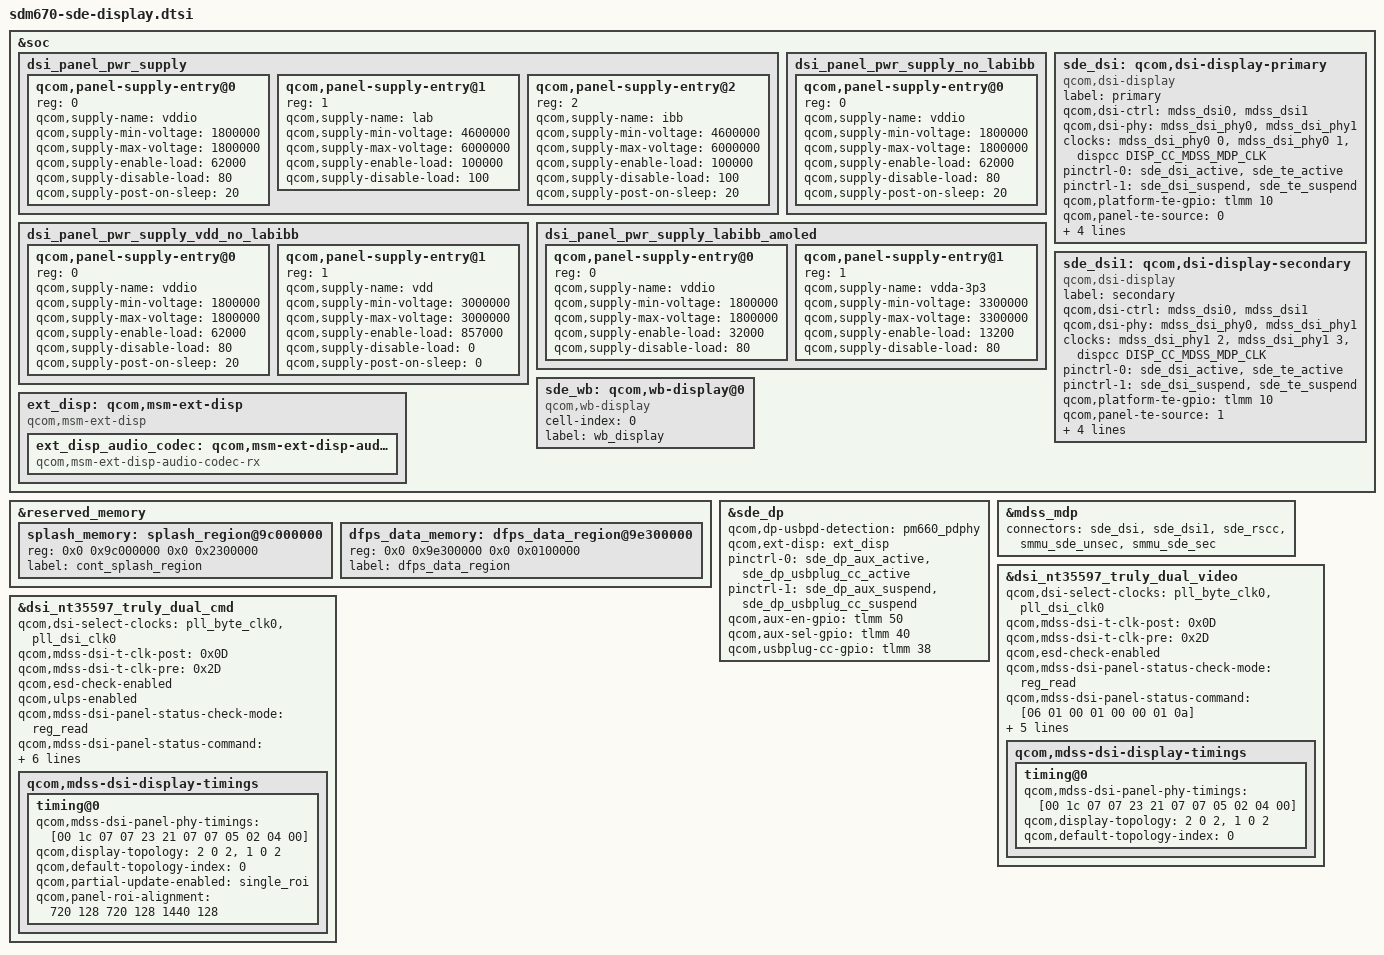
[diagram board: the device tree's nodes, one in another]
#include "sdm670-sde.dtsi"
#include "dsi-panel-nt35597-truly-wqxga-dualmipi-video.dtsi"
#include "dsi-panel-nt35597-truly-wqxga-dualmipi-cmd.dtsi"

&soc {
	dsi_panel_pwr_supply: dsi_panel_pwr_supply {
		#address-cells = <1>;
		#size-cells = <0>;

		qcom,panel-supply-entry@0 {
			reg = <0>;
			qcom,supply-name = "vddio";
			qcom,supply-min-voltage = <1800000>;
			qcom,supply-max-voltage = <1800000>;
			qcom,supply-enable-load = <62000>;
			qcom,supply-disable-load = <80>;
			qcom,supply-post-on-sleep = <20>;
		};

		qcom,panel-supply-entry@1 {
			reg = <1>;
			qcom,supply-name = "lab";
			qcom,supply-min-voltage = <4600000>;
			qcom,supply-max-voltage = <6000000>;
			qcom,supply-enable-load = <100000>;
			qcom,supply-disable-load = <100>;
		};

		qcom,panel-supply-entry@2 {
			reg = <2>;
			qcom,supply-name = "ibb";
			qcom,supply-min-voltage = <4600000>;
			qcom,supply-max-voltage = <6000000>;
			qcom,supply-enable-load = <100000>;
			qcom,supply-disable-load = <100>;
			qcom,supply-post-on-sleep = <20>;
		};
	};

	dsi_panel_pwr_supply_no_labibb: dsi_panel_pwr_supply_no_labibb {
		#address-cells = <1>;
		#size-cells = <0>;

		qcom,panel-supply-entry@0 {
			reg = <0>;
			qcom,supply-name = "vddio";
			qcom,supply-min-voltage = <1800000>;
			qcom,supply-max-voltage = <1800000>;
			qcom,supply-enable-load = <62000>;
			qcom,supply-disable-load = <80>;
			qcom,supply-post-on-sleep = <20>;
		};
	};

	dsi_panel_pwr_supply_vdd_no_labibb: dsi_panel_pwr_supply_vdd_no_labibb {
		#address-cells = <1>;
		#size-cells = <0>;

		qcom,panel-supply-entry@0 {
			reg = <0>;
			qcom,supply-name = "vddio";
			qcom,supply-min-voltage = <1800000>;
			qcom,supply-max-voltage = <1800000>;
			qcom,supply-enable-load = <62000>;
			qcom,supply-disable-load = <80>;
			qcom,supply-post-on-sleep = <20>;
		};

		qcom,panel-supply-entry@1 {
			reg = <1>;
			qcom,supply-name = "vdd";
			qcom,supply-min-voltage = <3000000>;
			qcom,supply-max-voltage = <3000000>;
			qcom,supply-enable-load = <857000>;
			qcom,supply-disable-load = <0>;
			qcom,supply-post-on-sleep = <0>;
		};
	};

	dsi_panel_pwr_supply_labibb_amoled: dsi_panel_pwr_supply_labibb_amoled {
		#address-cells = <1>;
		#size-cells = <0>;

		qcom,panel-supply-entry@0 {
			reg = <0>;
			qcom,supply-name = "vddio";
			qcom,supply-min-voltage = <1800000>;
			qcom,supply-max-voltage = <1800000>;
			qcom,supply-enable-load = <32000>;
			qcom,supply-disable-load = <80>;
		};

		qcom,panel-supply-entry@1 {
			reg = <1>;
			qcom,supply-name = "vdda-3p3";
			qcom,supply-min-voltage = <3300000>;
			qcom,supply-max-voltage = <3300000>;
			qcom,supply-enable-load = <13200>;
			qcom,supply-disable-load = <80>;
		};
	};

	sde_dsi: qcom,dsi-display-primary {
		compatible = "qcom,dsi-display";
		label = "primary";

		qcom,dsi-ctrl = <&mdss_dsi0 &mdss_dsi1>;
		qcom,dsi-phy = <&mdss_dsi_phy0 &mdss_dsi_phy1>;

		clocks = <&mdss_dsi_phy0 0>,
			 <&mdss_dsi_phy0 1>,
			/*
			* Currently the dsi clock handles are under the dsi
			* controller DT node. As soon as the controller probe
			* finishes, the dispcc sync state can get called before
			* the dsi_display probe potentially disturbing the clock
			* votes for cont_splash use case. Hence we are no longer
			* protected by the component model in this case against the
			* disp cc sync state getting triggered after the dsi_ctrl
			* probe. To protect against this incorrect sync state trigger
			* add this dummy MDP clk vote handle to the dsi_display
			* DT node. Since the dsi_display driver does not parse
			* MDP clock nodes, no actual vote shall be added and this
			* change is done just to satisfy sync state requirements.
			*/
			<&dispcc DISP_CC_MDSS_MDP_CLK>;
		clock-names = "pll_byte_clk0", "pll_dsi_clk0",
				"mdp_core_clk";

		pinctrl-names = "panel_active", "panel_suspend";
		pinctrl-0 = <&sde_dsi_active &sde_te_active>;
		pinctrl-1 = <&sde_dsi_suspend &sde_te_suspend>;

		qcom,platform-te-gpio = <&tlmm 10 0>;
		qcom,panel-te-source = <0>;

		vddio-supply = <&pm660_l11>;
		lab-supply = <&lcdb_ldo_vreg>;
		ibb-supply = <&lcdb_ncp_vreg>;

		qcom,mdp = <&mdss_mdp>;
	};

	sde_dsi1: qcom,dsi-display-secondary {
		compatible = "qcom,dsi-display";
		label = "secondary";

		qcom,dsi-ctrl = <&mdss_dsi0 &mdss_dsi1>;
		qcom,dsi-phy = <&mdss_dsi_phy0 &mdss_dsi_phy1>;

		clocks = <&mdss_dsi_phy1 2>,
			 <&mdss_dsi_phy1 3>,
			/*
			* Currently the dsi clock handles are under the dsi
			* controller DT node. As soon as the controller probe
			* finishes, the dispcc sync state can get called before
			* the dsi_display probe potentially disturbing the clock
			* votes for cont_splash use case. Hence we are no longer
			* protected by the component model in this case against the
			* disp cc sync state getting triggered after the dsi_ctrl
			* probe. To protect against this incorrect sync state trigger
			* add this dummy MDP clk vote handle to the dsi_display
			* DT node. Since the dsi_display driver does not parse
			* MDP clock nodes, no actual vote shall be added and this
			* change is done just to satisfy sync state requirements.
			*/
			<&dispcc DISP_CC_MDSS_MDP_CLK>;
		clock-names = "pll_byte_clk1", "pll_dsi_clk1",
				"mdp_core_clk";

		pinctrl-names = "panel_active", "panel_suspend";
		pinctrl-0 = <&sde_dsi_active &sde_te_active>;
		pinctrl-1 = <&sde_dsi_suspend &sde_te_suspend>;

		qcom,platform-te-gpio = <&tlmm 10 0>;
		qcom,panel-te-source = <1>;

		vddio-supply = <&pm660_l11>;
		lab-supply = <&lcdb_ldo_vreg>;
		ibb-supply = <&lcdb_ncp_vreg>;

		qcom,mdp = <&mdss_mdp>;
	};

	sde_wb: qcom,wb-display@0 {
		compatible = "qcom,wb-display";
		cell-index = <0>;
		label = "wb_display";
	};

	ext_disp: qcom,msm-ext-disp {
		compatible = "qcom,msm-ext-disp";

		ext_disp_audio_codec: qcom,msm-ext-disp-audio-codec-rx {
			compatible = "qcom,msm-ext-disp-audio-codec-rx";
		};
	};
};

&reserved_memory {
	splash_memory: splash_region@9c000000 {
		reg = <0x0 0x9c000000 0x0 0x2300000>;
		label = "cont_splash_region";
	};

	dfps_data_memory: dfps_data_region@9e300000 {
		reg = <0x0 0x9e300000 0x0 0x0100000>;
		label = "dfps_data_region";
	};
};

&sde_dp {
	qcom,dp-usbpd-detection = <&pm660_pdphy>;
	qcom,ext-disp = <&ext_disp>;

	pinctrl-names = "mdss_dp_active", "mdss_dp_sleep";
	pinctrl-0 = <&sde_dp_aux_active &sde_dp_usbplug_cc_active>;
	pinctrl-1 = <&sde_dp_aux_suspend &sde_dp_usbplug_cc_suspend>;
	qcom,aux-en-gpio = <&tlmm 50 0>;
	qcom,aux-sel-gpio = <&tlmm 40 0>;
	qcom,usbplug-cc-gpio = <&tlmm 38 0>;
};

&mdss_mdp {
	connectors = <&sde_dsi &sde_dsi1 &sde_rscc
		&smmu_sde_unsec &smmu_sde_sec>;
};

&dsi_nt35597_truly_dual_video {
	qcom,dsi-select-clocks = "pll_byte_clk0", "pll_dsi_clk0";
	qcom,mdss-dsi-t-clk-post = <0x0D>;
	qcom,mdss-dsi-t-clk-pre = <0x2D>;
	qcom,esd-check-enabled;
	qcom,mdss-dsi-panel-status-check-mode = "reg_read";
	qcom,mdss-dsi-panel-status-command = [06 01 00 01 00 00 01 0a];
	qcom,mdss-dsi-panel-status-command-state = "dsi_hs_mode";
	qcom,mdss-dsi-panel-status-value = <0x9c>;
	qcom,mdss-dsi-panel-on-check-value = <0x9c>;
	qcom,mdss-dsi-panel-status-read-length = <1>;

	qcom,mdss-dsi-display-timings {
		timing@0{
			qcom,mdss-dsi-panel-phy-timings = [00 1c 07 07 23 21 07
				07 05 02 04 00];
			qcom,display-topology = <2 0 2>,
						<1 0 2>;
			qcom,default-topology-index = <0>;
		};
	};
};

&dsi_nt35597_truly_dual_cmd {
	qcom,dsi-select-clocks = "pll_byte_clk0", "pll_dsi_clk0";
	qcom,mdss-dsi-t-clk-post = <0x0D>;
	qcom,mdss-dsi-t-clk-pre = <0x2D>;
	qcom,esd-check-enabled;
	qcom,ulps-enabled;
	qcom,mdss-dsi-panel-status-check-mode = "reg_read";
	qcom,mdss-dsi-panel-status-command = [06 01 00 01 00 00 01 0a];
	qcom,mdss-dsi-panel-status-command-state = "dsi_hs_mode";
	qcom,mdss-dsi-panel-status-value = <0x9c>;
	qcom,mdss-dsi-panel-on-check-value = <0x9c>;
	qcom,mdss-dsi-panel-status-read-length = <1>;
	qcom,mdss-dsi-display-timings {
		timing@0{
			qcom,mdss-dsi-panel-phy-timings = [00 1c 07 07 23 21 07
				07 05 02 04 00];
			qcom,display-topology = <2 0 2>,
						<1 0 2>;
			qcom,default-topology-index = <0>;
			qcom,partial-update-enabled = "single_roi";
			qcom,panel-roi-alignment = <720 128 720 128 1440 128>;
		};
	};
};
